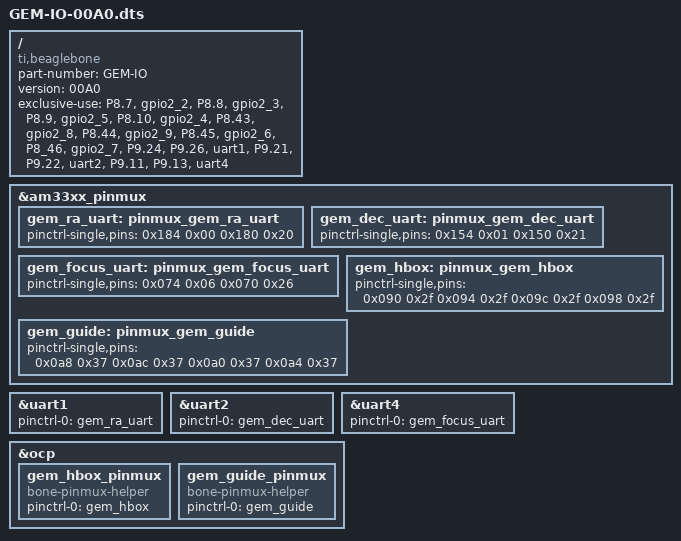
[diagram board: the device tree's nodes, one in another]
/dts-v1/;
/plugin/;

/ {
    compatible = "ti,beaglebone", "ti,beaglebone-black";

    part-number = "GEM-IO";
    version = "00A0";

    exclusive-use =

        "P8.7", "gpio2_2",                            // handbox GPIO pins
        "P8.8", "gpio2_3",
        "P8.9", "gpio2_5",
        "P8.10", "gpio2_4",

	"P8.43", "gpio2_8",                           // guide GIPO pins
        "P8.44", "gpio2_9",
        "P8.45", "gpio2_6",
        "P8_46", "gpio2_7",

        "P9.24", "P9.26", "uart1",                    // motion control RS-422
        "P9.21", "P9.22", "uart2",
        "P9.11", "P9.13", "uart4";

// UART 1 is connected to RA motion controller

    fragment@0 {
        target = <&am33xx_pinmux>;
        __overlay__ {
            gem_ra_uart: pinmux_gem_ra_uart {
                pinctrl-single,pins = <
                    0x184 0x00             // P9.24 mode0 output (tx)
                    0x180 0x20             // P9.26 mode0 input (rx)
                >;
            };
        };
    };

    fragment@1 {
        target = <&uart1>;
        __overlay__ {
            status = "okay";
            pinctrl-names = "default";
            pinctrl-0 = <&gem_ra_uart>;
        };
    };

// UART 2 is connected to DEC motion controller

    fragment@2 {
        target = <&am33xx_pinmux>;
        __overlay__ {
            gem_dec_uart: pinmux_gem_dec_uart {
                pinctrl-single,pins = <
                    0x154 0x01             // P9.21 mode1 output (tx)
                    0x150 0x21             // P9.22 mode1 input (rx)
                >;
            };
        };
    };

    fragment@3 {
        target = <&uart2>;
        __overlay__ {
            status = "okay";
            pinctrl-names = "default";
            pinctrl-0 = <&gem_dec_uart>;
        };
    };

// UART 4 is connected to focus motion controller

    fragment@4 {
        target = <&am33xx_pinmux>;
        __overlay__ {
            gem_focus_uart: pinmux_gem_focus_uart {
                pinctrl-single,pins = <
                    0x074 0x06             // P9.13 mode6 output (tx)
                    0x070 0x26             // P9.11 mode6 input (rx)
                >;
            };
        };
    };

    fragment@5 {
        target = <&uart4>;
        __overlay__ {
            status = "okay";
            pinctrl-names = "default";
            pinctrl-0 = <&gem_focus_uart>;
        };
    };


// 4 GPIO inputs are connected to handbox, with external pull-downs

    fragment@6 {
        target = <&am33xx_pinmux>;
        __overlay__ {
            gem_hbox: pinmux_gem_hbox {
                pinctrl-single,pins = <
                    0x090 0x2f             // P8.7 mode7 input
                    0x094 0x2f             // P8.8 mode7 input
                    0x09c 0x2f             // P8.9 mode7 input
                    0x098 0x2f             // P8.10 mode7 input
                >;
            };
        };
    };

    fragment@7 {
        target = <&ocp>;
        __overlay__ {
            gem_hbox_pinmux {
                compatible = "bone-pinmux-helper";
                status = "okay";
                pinctrl-names = "default";
                pinctrl-0 = <&gem_hbox>;
            };
        };
    };

// 4 GPIO inputs are connected to guide port (internal pull-ups)

    fragment@8 {
        target = <&am33xx_pinmux>;
        __overlay__ {
            gem_guide: pinmux_gem_guide {
                pinctrl-single,pins = <
                    0x0a8 0x37             // P8.43 mode7 input + p/u
                    0x0ac 0x37             // P8.44 mode7 input + p/u
                    0x0a0 0x37             // P8.45 mode7 input + p/u
                    0x0a4 0x37             // P8.46 mode7 input + p/u
                >;
            };
        };
    };

    fragment@9 {
        target = <&ocp>;
        __overlay__ {
            gem_guide_pinmux {
                compatible = "bone-pinmux-helper";
                status = "okay";
                pinctrl-names = "default";
                pinctrl-0 = <&gem_guide>;
            };
        };
    };

};
